VERSION "04/12/2025"

NS_ :

BS_:

BU_: RaceCapture

BO_ 171 InverterState: 8 RaceCapture
    SG_ InverterState    : 32|32@1+ (1,0)        [0|4294967295]     ""      RaceCapture

BO_ 406385536 ThermistorExpansion: 8 RaceCapture
    SG_ ThermVal         : 16|8@1-  (1,0)        [-40|80]           "C"     RaceCapture
    SG_ ThermID          : 32|8@1+  (1,0)        [1|80]             ""      RaceCapture
    SG_ ThermMax         : 40|8@1-  (1,0)        [-40|80]           "C"     RaceCapture
    SG_ ThermMaxID       : 48|8@1+  (1,0)        [1|80]             ""      RaceCapture
    SG_ ThermMin         : 36|8@1-  (1,0)        [-40|80]           "C"     RaceCapture
    SG_ ThermMinID       : 56|8@1+  (1,0)        [1|80]             ""      RaceCapture

BO_ 1714 OrionSummary1: 8 RaceCapture
    SG_ IMD_Fault        :  0|1@1+  (1,0)        [0|1]              ""      RaceCapture
    SG_ BMS_Fault        :  8|1@1+  (1,0)        [0|1]              ""      RaceCapture
    SG_ PackVoltage      : 16|16@0- (0.1,0)      [-3276.8|3276.7]   "V"     RaceCapture
    SG_ PackCurrent      : 32|16@0- (0.1,0)      [-3276.8|3276.7]   "A"     RaceCapture
    SG_ PackPower        : 48|16@0- (0.1,0)      [-3276.8|3276.7]   "kW"    RaceCapture

BO_ 1715 OrionSummary2: 8 RaceCapture
    SG_ ThermAvg         : 16|8@1-  (1,0)        [-40|80]           "C"     RaceCapture

BO_ 167 InverterElectrical: 8 RaceCapture
    SG_ OutputV          : 16|16@1- (0.1,0)      [-3276.8|3276.7]   "V"     RaceCapture

BO_ 172 InverterTorque: 8 RaceCapture
    SG_ Torque           : 32|16@1- (0.1,0)      [-3276.8|3276.7]   "Nm"    RaceCapture

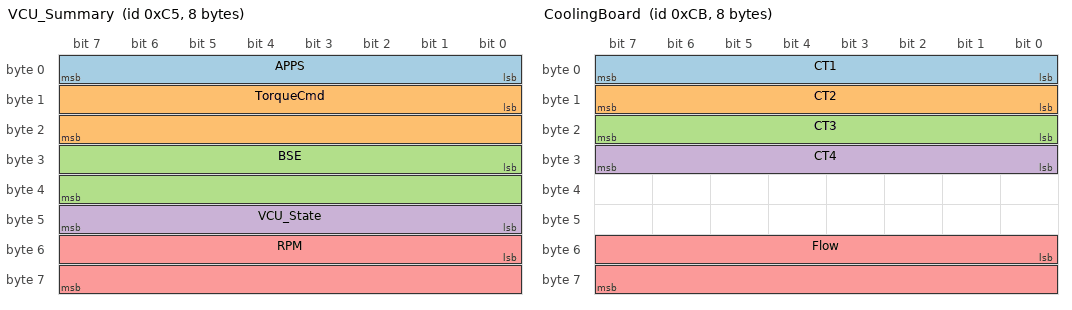
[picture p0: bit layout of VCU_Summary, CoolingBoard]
BO_ 197 VCU_Summary: 8 RaceCapture
    SG_ APPS             :  0|8@1+  (1,0)        [0|100]            "%"     RaceCapture
    SG_ TorqueCmd        :  8|16@1+ (0.1,0)      [0|65535]          "Nm"    RaceCapture
    SG_ BSE              : 24|16@1+ (1,0)        [0|5000]           "mV"    RaceCapture
    SG_ VCU_State        : 40|8@1+  (1,0)        [0|4]              ""      RaceCapture
    SG_ RPM              : 48|16@1- (1,0)        [-32768|32767]     "RPM"   RaceCapture

BO_ 219 VCU_Debug: 8 RaceCapture
    SG_ APPS_Err         :  0|1@1-  (1,0)        [0|2]              ""      RaceCapture
    SG_ BSE_Err          :  8|1@1-  (1,0)        [0|1]              ""      RaceCapture

BO_ 203 CoolingBoard: 8 RaceCapture
    SG_ CT1              :  0|8@1-  (1,0)        [-40|120]          "C"     RaceCapture
    SG_ CT2              :  8|8@1-  (1,0)        [-40|120]          "C"     RaceCapture
    SG_ CT3              : 16|8@1-  (1,0)        [-40|120]          "C"     RaceCapture
    SG_ CT4              : 24|8@1-  (1,0)        [-40|120]          "C"     RaceCapture
    SG_ Flow             : 48|16@1+ (0.1,0)      [0|30]             "L/min" RaceCapture
